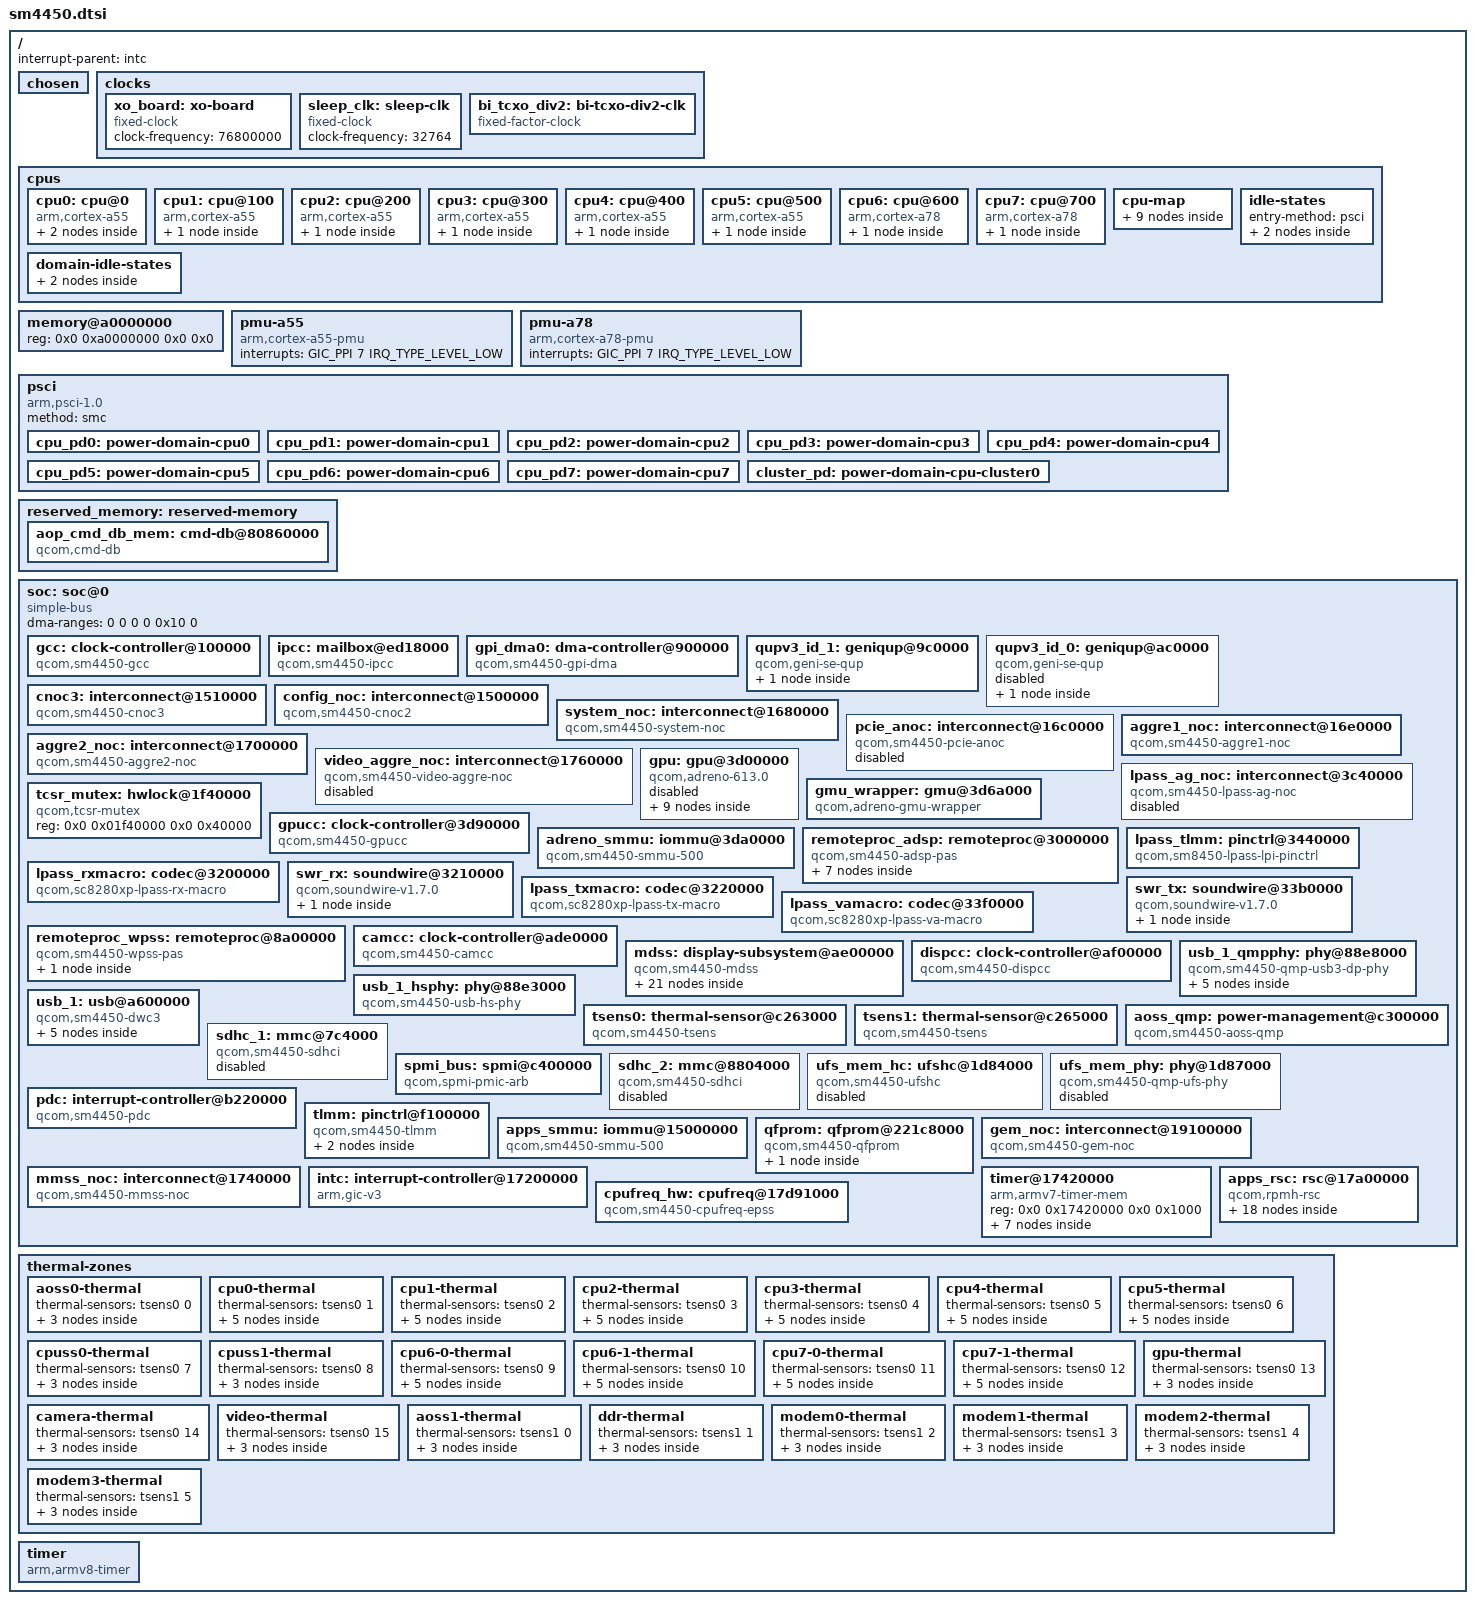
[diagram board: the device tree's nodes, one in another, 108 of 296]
// SPDX-License-Identifier: BSD-3-Clause
/*
 * Copyright (c) 2023, Qualcomm Innovation Center, Inc. All rights reserved.
 */

#include <dt-bindings/clock/qcom,dsi-phy-28nm.h>
#include <dt-bindings/clock/qcom,rpmh.h>
#include <dt-bindings/clock/qcom,sm4450-camcc.h>
#include <dt-bindings/clock/qcom,sm4450-dispcc.h>
#include <dt-bindings/clock/qcom,sm4450-gcc.h>
#include <dt-bindings/clock/qcom,sm4450-gpucc.h>
#include <dt-bindings/dma/qcom-gpi.h>
#include <dt-bindings/gpio/gpio.h>
#include <dt-bindings/interrupt-controller/arm-gic.h>
#include <dt-bindings/interconnect/qcom,icc.h>
#include <dt-bindings/interconnect/qcom,sm4450-rpmh.h>
#include <dt-bindings/mailbox/qcom-ipcc.h>
#include <dt-bindings/power/qcom,rpmhpd.h>
#include <dt-bindings/power/qcom-rpmpd.h>
#include <dt-bindings/soc/qcom,rpmh-rsc.h>
#include <dt-bindings/soc/qcom,gpr.h>
#include <dt-bindings/sound/qcom,q6dsp-lpass-ports.h>
#include <dt-bindings/phy/phy-qcom-qmp.h>
#include <dt-bindings/thermal/thermal.h>

/ {
	interrupt-parent = <&intc>;

	#address-cells = <2>;
	#size-cells = <2>;

	chosen { };

	clocks {
		xo_board: xo-board {
			compatible = "fixed-clock";
			clock-frequency = <76800000>;
			#clock-cells = <0>;
		};

		sleep_clk: sleep-clk {
			compatible = "fixed-clock";
			clock-frequency = <32764>;
			#clock-cells = <0>;
		};

		bi_tcxo_div2: bi-tcxo-div2-clk {
			#clock-cells = <0>;
			compatible = "fixed-factor-clock";
			clocks = <&rpmhcc RPMH_CXO_CLK>;
			clock-mult = <1>;
			clock-div = <2>;
		};
	};

	cpus {
		#address-cells = <2>;
		#size-cells = <0>;

		cpu0: cpu@0 {
			device_type = "cpu";
			compatible = "arm,cortex-a55";
			reg = <0x0 0x0>;
			capacity-dmips-mhz = <1024>;
			dynamic-power-coefficient = <100>;
			clocks = <&cpufreq_hw 0>;
			enable-method = "psci";
			next-level-cache = <&l2_0>;
			power-domains = <&cpu_pd0>;
			power-domain-names = "psci";
			qcom,freq-domain = <&cpufreq_hw 0>;
			#cooling-cells = <2>;

			l2_0: l2-cache {
				compatible = "cache";
				cache-level = <2>;
				cache-unified;
				next-level-cache = <&l3_0>;

				l3_0: l3-cache {
					compatible = "cache";
					cache-level = <3>;
					cache-unified;
				};
			};
		};

		cpu1: cpu@100 {
			device_type = "cpu";
			compatible = "arm,cortex-a55";
			reg = <0x0 0x100>;
			capacity-dmips-mhz = <1024>;
			dynamic-power-coefficient = <100>;
			clocks = <&cpufreq_hw 0>;
			enable-method = "psci";
			next-level-cache = <&l2_100>;
			power-domains = <&cpu_pd0>;
			power-domain-names = "psci";
			qcom,freq-domain = <&cpufreq_hw 0>;
			#cooling-cells = <2>;

			l2_100: l2-cache {
				compatible = "cache";
				cache-level = <2>;
				cache-unified;
				next-level-cache = <&l3_0>;
			};
		};

		cpu2: cpu@200 {
			device_type = "cpu";
			compatible = "arm,cortex-a55";
			reg = <0x0 0x200>;
			capacity-dmips-mhz = <1024>;
			dynamic-power-coefficient = <100>;
			clocks = <&cpufreq_hw 0>;
			enable-method = "psci";
			next-level-cache = <&l2_200>;
			power-domains = <&cpu_pd0>;
			power-domain-names = "psci";
			qcom,freq-domain = <&cpufreq_hw 0>;
			#cooling-cells = <2>;

			l2_200: l2-cache {
				compatible = "cache";
				cache-level = <2>;
				cache-unified;
				next-level-cache = <&l3_0>;
			};
		};

		cpu3: cpu@300 {
			device_type = "cpu";
			compatible = "arm,cortex-a55";
			reg = <0x0 0x300>;
			capacity-dmips-mhz = <1024>;
			dynamic-power-coefficient = <100>;
			clocks = <&cpufreq_hw 0>;
			enable-method = "psci";
			next-level-cache = <&l2_300>;
			power-domains = <&cpu_pd0>;
			power-domain-names = "psci";
			qcom,freq-domain = <&cpufreq_hw 0>;
			#cooling-cells = <2>;

			l2_300: l2-cache {
				compatible = "cache";
				cache-level = <2>;
				cache-unified;
				next-level-cache = <&l3_0>;
			};
		};

		cpu4: cpu@400 {
			device_type = "cpu";
			compatible = "arm,cortex-a55";
			reg = <0x0 0x400>;
			capacity-dmips-mhz = <1024>;
			dynamic-power-coefficient = <100>;
			clocks = <&cpufreq_hw 0>;
			enable-method = "psci";
			next-level-cache = <&l2_400>;
			power-domains = <&cpu_pd0>;
			power-domain-names = "psci";
			qcom,freq-domain = <&cpufreq_hw 0>;
			#cooling-cells = <2>;

			l2_400: l2-cache {
				compatible = "cache";
				cache-level = <2>;
				cache-unified;
				next-level-cache = <&l3_0>;
			};
		};

		cpu5: cpu@500 {
			device_type = "cpu";
			compatible = "arm,cortex-a55";
			reg = <0x0 0x500>;
			capacity-dmips-mhz = <1024>;
			dynamic-power-coefficient = <100>;
			clocks = <&cpufreq_hw 0>;
			enable-method = "psci";
			next-level-cache = <&l2_500>;
			power-domains = <&cpu_pd0>;
			power-domain-names = "psci";
			qcom,freq-domain = <&cpufreq_hw 0>;
			#cooling-cells = <2>;

			l2_500: l2-cache {
				compatible = "cache";
				cache-level = <2>;
				cache-unified;
				next-level-cache = <&l3_0>;
			};
		};

		cpu6: cpu@600 {
			device_type = "cpu";
			compatible = "arm,cortex-a78";
			reg = <0x0 0x600>;
			capacity-dmips-mhz = <1894>;
			dynamic-power-coefficient = <703>;
			clocks = <&cpufreq_hw 1>;
			enable-method = "psci";
			next-level-cache = <&l2_600>;
			power-domains = <&cpu_pd0>;
			power-domain-names = "psci";
			qcom,freq-domain = <&cpufreq_hw 1>;
			#cooling-cells = <2>;

			l2_600: l2-cache {
				compatible = "cache";
				cache-level = <2>;
				cache-unified;
				next-level-cache = <&l3_0>;
			};
		};

		cpu7: cpu@700 {
			device_type = "cpu";
			compatible = "arm,cortex-a78";
			reg = <0x0 0x700>;
			capacity-dmips-mhz = <1894>;
			dynamic-power-coefficient = <703>;
			clocks = <&cpufreq_hw 1>;
			enable-method = "psci";
			next-level-cache = <&l2_700>;
			power-domains = <&cpu_pd0>;
			power-domain-names = "psci";
			qcom,freq-domain = <&cpufreq_hw 1>;
			#cooling-cells = <2>;

			l2_700: l2-cache {
				compatible = "cache";
				cache-level = <2>;
				cache-unified;
				next-level-cache = <&l3_0>;
			};
		};

		cpu-map {
			cluster0 {
				core0 {
					cpu = <&cpu0>;
				};

				core1 {
					cpu = <&cpu1>;
				};

				core2 {
					cpu = <&cpu2>;
				};

				core3 {
					cpu = <&cpu3>;
				};

				core4 {
					cpu = <&cpu4>;
				};

				core5 {
					cpu = <&cpu5>;
				};

				core6 {
					cpu = <&cpu6>;
				};

				core7 {
					cpu = <&cpu7>;
				};
			};
		};

		idle-states {
			entry-method = "psci";

			little_cpu_sleep_0: cpu-sleep-0-0 {
				compatible = "arm,idle-state";
				arm,psci-suspend-param = <0x40000004>;
				entry-latency-us = <800>;
				exit-latency-us = <750>;
				min-residency-us = <4090>;
				local-timer-stop;
			};

			big_cpu_sleep_0: cpu-sleep-1-0 {
				compatible = "arm,idle-state";
				arm,psci-suspend-param = <0x40000004>;
				entry-latency-us = <600>;
				exit-latency-us = <1550>;
				min-residency-us = <4791>;
				local-timer-stop;
			};
		};

		domain-idle-states {
			cluster_sleep_0: cluster-sleep-0 {
				compatible = "domain-idle-state";
				arm,psci-suspend-param = <0x41000044>;
				entry-latency-us = <1050>;
				exit-latency-us = <2500>;
				min-residency-us = <5309>;
			};

			cluster_sleep_1: cluster-sleep-1 {
				compatible = "domain-idle-state";
				arm,psci-suspend-param = <0x41003344>;
				entry-latency-us = <1561>;
				exit-latency-us = <2801>;
				min-residency-us = <8550>;
			};
		};
	};

	memory@a0000000 {
		device_type = "memory";
		/* We expect the bootloader to fill in the size */
		reg = <0x0 0xa0000000 0x0 0x0>;
	};

	pmu-a55 {
		compatible = "arm,cortex-a55-pmu";
		interrupts = <GIC_PPI 7 IRQ_TYPE_LEVEL_LOW>;
	};

	pmu-a78 {
		compatible = "arm,cortex-a78-pmu";
		interrupts = <GIC_PPI 7 IRQ_TYPE_LEVEL_LOW>;
	};

	psci {
		compatible = "arm,psci-1.0";
		method = "smc";

		cpu_pd0: power-domain-cpu0 {
			#power-domain-cells = <0>;
			power-domains = <&cluster_pd>;
			domain-idle-states = <&little_cpu_sleep_0>;
		};

		cpu_pd1: power-domain-cpu1 {
			#power-domain-cells = <0>;
			power-domains = <&cluster_pd>;
			domain-idle-states = <&little_cpu_sleep_0>;
		};

		cpu_pd2: power-domain-cpu2 {
			#power-domain-cells = <0>;
			power-domains = <&cluster_pd>;
			domain-idle-states = <&little_cpu_sleep_0>;
		};

		cpu_pd3: power-domain-cpu3 {
			#power-domain-cells = <0>;
			power-domains = <&cluster_pd>;
			domain-idle-states = <&little_cpu_sleep_0>;
		};

		cpu_pd4: power-domain-cpu4 {
			#power-domain-cells = <0>;
			power-domains = <&cluster_pd>;
			domain-idle-states = <&big_cpu_sleep_0>;
		};

		cpu_pd5: power-domain-cpu5 {
			#power-domain-cells = <0>;
			power-domains = <&cluster_pd>;
			domain-idle-states = <&big_cpu_sleep_0>;
		};

		cpu_pd6: power-domain-cpu6 {
			#power-domain-cells = <0>;
			power-domains = <&cluster_pd>;
			domain-idle-states = <&big_cpu_sleep_0>;
		};

		cpu_pd7: power-domain-cpu7 {
			#power-domain-cells = <0>;
			power-domains = <&cluster_pd>;
			domain-idle-states = <&big_cpu_sleep_0>;
		};

		cluster_pd: power-domain-cpu-cluster0 {
			#power-domain-cells = <0>;
			domain-idle-states = <&cluster_sleep_0>, <&cluster_sleep_1>;
		};
	};

	reserved_memory: reserved-memory {
		#address-cells = <2>;
		#size-cells = <2>;
		ranges;

		aop_cmd_db_mem: cmd-db@80860000 {
			compatible = "qcom,cmd-db";
			reg = <0x0 0x80860000 0x0 0x20000>;
			no-map;
		};
	};

	soc: soc@0 {
		#address-cells = <2>;
		#size-cells = <2>;
		ranges = <0 0 0 0 0x10 0>;
		dma-ranges = <0 0 0 0 0x10 0>;
		compatible = "simple-bus";

		gcc: clock-controller@100000 {
			compatible = "qcom,sm4450-gcc";
			reg = <0x0 0x00100000 0x0 0x1f4200>;
			#clock-cells = <1>;
			#reset-cells = <1>;
			#power-domain-cells = <1>;
			clocks = <&rpmhcc RPMH_CXO_CLK>,
				 <&sleep_clk>,
				 <0>,
				 <0>,
				 <0>,
				 <0>;
		};

		ipcc: mailbox@ed18000 {
			compatible = "qcom,sm4450-ipcc", "qcom,ipcc";
			reg = <0x0 0x0ed18000 0x0 0x1000>;
			interrupts = <GIC_SPI 229 IRQ_TYPE_LEVEL_HIGH>;
			interrupt-controller;
			#interrupt-cells = <3>;
			#mbox-cells = <2>;
		};

		gpi_dma0: dma-controller@900000 {
			compatible = "qcom,sm4450-gpi-dma", "qcom,sm6350-gpi-dma";
			reg = <0x0 0x00900000 0x0 0x60000>;
			interrupts = <GIC_SPI 244 IRQ_TYPE_LEVEL_HIGH>,
				<GIC_SPI 245 IRQ_TYPE_LEVEL_HIGH>,
				<GIC_SPI 246 IRQ_TYPE_LEVEL_HIGH>,
				<GIC_SPI 247 IRQ_TYPE_LEVEL_HIGH>,
				<GIC_SPI 248 IRQ_TYPE_LEVEL_HIGH>,
				<GIC_SPI 249 IRQ_TYPE_LEVEL_HIGH>,
				<GIC_SPI 250 IRQ_TYPE_LEVEL_HIGH>,
				<GIC_SPI 251 IRQ_TYPE_LEVEL_HIGH>,
				<GIC_SPI 252 IRQ_TYPE_LEVEL_HIGH>,
				<GIC_SPI 253 IRQ_TYPE_LEVEL_HIGH>,
				<GIC_SPI 254 IRQ_TYPE_LEVEL_HIGH>,
				<GIC_SPI 255 IRQ_TYPE_LEVEL_HIGH>;
			dma-channels = <12>;
			dma-channel-mask = <0x3e>;
			iommus = <&apps_smmu 0x176 0x0>;
			#dma-cells = <3>;
		};

		qupv3_id_1: geniqup@9c0000 {
			compatible = "qcom,geni-se-qup";
			reg = <0x0 0x009c0000 0x0 0x2000>;
			ranges;
			iommus = <&apps_smmu 0x163 0x0>;
			clocks = <&gcc GCC_QUPV3_WRAP_0_M_AHB_CLK>,
				 <&gcc GCC_QUPV3_WRAP_0_S_AHB_CLK>;
			clock-names = "m-ahb", "s-ahb";
			#address-cells = <2>;
			#size-cells = <2>;
			status = "okay";

			uart2: serial@988000 {
				compatible = "qcom,geni-uart";
				reg = <0x0 0x00988000 0x0 0x4000>;
				clocks = <&gcc GCC_QUPV3_WRAP0_S2_CLK>;
				clock-names = "se";
				interrupts-extended = <&intc GIC_SPI 603 IRQ_TYPE_LEVEL_HIGH>,
					    	  <&tlmm 17 IRQ_TYPE_EDGE_FALLING>;
				interconnects = <&clk_virt MASTER_QUP_CORE_0 QCOM_ICC_TAG_ALWAYS
						 &clk_virt SLAVE_QUP_CORE_0 QCOM_ICC_TAG_ALWAYS>,
						<&gem_noc MASTER_APPSS_PROC QCOM_ICC_TAG_ALWAYS
					 	&config_noc SLAVE_QUP_0 QCOM_ICC_TAG_ALWAYS>;
				interconnect-names = "qup-core", "qup-config";
				pinctrl-0 = <&qup_uart2_default>;
				pinctrl-1 = <&qup_uart2_sleep>;
				pinctrl-names = "default", "sleep";
				status = "okay";
			};
		};
		
		qupv3_id_0: geniqup@ac0000 {
			compatible = "qcom,geni-se-qup";
			reg = <0x0 0x00ac0000 0x0 0x2000>;
			ranges;
			clocks = <&gcc GCC_QUPV3_WRAP_1_M_AHB_CLK>,
				 <&gcc GCC_QUPV3_WRAP_1_S_AHB_CLK>;
			clock-names = "m-ahb", "s-ahb";
			#address-cells = <2>;
			#size-cells = <2>;
			status = "disabled";

			uart7: serial@a88000 {
				compatible = "qcom,geni-debug-uart";
				reg = <0x0 0x00a88000 0x0 0x4000>;
				clocks = <&gcc GCC_QUPV3_WRAP1_S2_CLK>;
				clock-names = "se";
				interrupts = <GIC_SPI 355 IRQ_TYPE_LEVEL_HIGH>;
				pinctrl-0 = <&qup_uart7_tx>, <&qup_uart7_rx>;
				pinctrl-names = "default";
				status = "disabled";
			};
		};

		cnoc3: interconnect@1510000 {
			compatible = "qcom,sm4450-cnoc3";
			reg = <0x0 0x01510000 0x0 0xf200>;
			#interconnect-cells = <2>;
			qcom,bcm-voters = <&apps_bcm_voter>;
		};

		config_noc: interconnect@1500000 {
			compatible = "qcom,sm4450-cnoc2";
			reg = <0x0 0x01500000 0x0 0x6200>;
			#interconnect-cells = <2>;
			qcom,bcm-voters = <&apps_bcm_voter>;
		};

		system_noc: interconnect@1680000 {
			compatible = "qcom,sm4450-system-noc";
			reg = <0x0 0x01680000 0x0 0x19080>;
			#interconnect-cells = <2>;
			qcom,bcm-voters = <&apps_bcm_voter>;
		};

		pcie_anoc: interconnect@16c0000 {
			compatible = "qcom,sm4450-pcie-anoc";
			reg = <0x0 0x016c0000 0x0 0x7080>;
			#interconnect-cells = <2>;
			qcom,bcm-voters = <&apps_bcm_voter>;
			status = "disabled";
		};

		aggre1_noc: interconnect@16e0000 {
			compatible = "qcom,sm4450-aggre1-noc";
			reg = <0x0 0x016e0000 0x0 0x13080>;
			#interconnect-cells = <2>;
			clocks = <&gcc GCC_SDCC2_AHB_CLK>;
			qcom,bcm-voters = <&apps_bcm_voter>;
		};

		aggre2_noc: interconnect@1700000 {
			compatible = "qcom,sm4450-aggre2-noc";
			reg = <0x0 0x01700000 0x0 0x1b080>;
			#interconnect-cells = <2>;
			clocks = <&rpmhcc RPMH_IPA_CLK>,
				 <&gcc GCC_AGGRE_USB3_PRIM_AXI_CLK>;
			qcom,bcm-voters = <&apps_bcm_voter>;
		};

		video_aggre_noc: interconnect@1760000 {
			compatible = "qcom,sm4450-video-aggre-noc";
			reg = <0x0 0x01760000 0x0 0x1100>;
			#interconnect-cells = <2>;
			qcom,bcm-voters = <&apps_bcm_voter>;
			status = "disabled";
		};

		lpass_ag_noc: interconnect@3c40000 {
			compatible = "qcom,sm4450-lpass-ag-noc";
			reg = <0x0 0x03c40000 0x0 0x17200>;
			#interconnect-cells = <2>;
			qcom,bcm-voters = <&apps_bcm_voter>;
			status = "disabled";
		};

		gpu: gpu@3d00000 {
			status = "disabled";
			compatible = "qcom,adreno-613.0", "qcom,adreno";
			reg = <0x0 0x03d00000 0x0 0x40000>,
				<0x0 0x03d9e000 0x0 0x1000>,
				<0x0 0x03d61000 0x0 0x800>;
			reg-names = "kgsl_3d0_reg_memory",
				"cx_mem",
				"cx_dbgc";

			interrupts = <GIC_SPI 300 IRQ_TYPE_LEVEL_HIGH>;

			clocks = <&gpucc GPU_CC_GX_GFX3D_CLK>,
				<&gpucc GPU_CC_AHB_CLK>,
				<&gcc GCC_DDRSS_GPU_AXI_CLK>,
				<&gcc GCC_GPU_MEMNOC_GFX_CLK>,
				<&gpucc GPU_CC_CX_GMU_CLK>,
				<&gpucc GPU_CC_CXO_CLK>,
				<&gpucc GPU_CC_HUB_CX_INT_CLK>;
			clock-names = "core",
					"iface",
					"mem_iface",
					"alt_mem_iface",
					"gmu",
					"xo",
					"hub";

			interconnects = <&gem_noc MASTER_GFX3D QCOM_ICC_TAG_ALWAYS
					&mc_virt SLAVE_EBI1 QCOM_ICC_TAG_ALWAYS>;
			interconnect-names = "gfx-mem";

			iommus = <&adreno_smmu 0 0x400>;
			power-domains = <&rpmhpd RPMHPD_CX>;

			operating-points-v2 = <&gpu_opp_table>;

			qcom,gmu = <&gmu_wrapper>;

			nvmem-cells = <&gpu_speed_bin>;
			nvmem-cell-names = "speed_bin";

			#cooling-cells = <2>;


			zap-shader {
				memory-region = <&gpu_microcode_mem>;
				firmware-name = "qcom/sm4450/a613_zap.mbn";
			};

			gpu_opp_table: opp-table {
				compatible = "operating-points-v2";

				opp-340000000 {
					opp-hz = /bits/ 64 <340000000>;
					required-opps = <&rpmhpd_opp_low_svs>;
					opp-peak-kBps = <2136718>;
					opp-supported-hw = <0xf>;
				};

				opp-500000000 {
					opp-hz = /bits/ 64 <500000000>;
					required-opps = <&rpmhpd_opp_svs>;
					opp-peak-kBps = <3972656>;
					opp-supported-hw = <0xf>;
				};

				opp-605000000 {
					opp-hz = /bits/ 64 <605000000>;
					required-opps = <&rpmhpd_opp_svs_l1>;
					opp-peak-kBps = <5285156>;
					opp-supported-hw = <0xf>;
				};

				opp-765000000 {
					opp-hz = /bits/ 64 <765000000>;
					required-opps = <&rpmhpd_opp_nom>;
					opp-peak-kBps = <6671875>;
					opp-supported-hw = <0xf>;
				};

				opp-850000000 {
					opp-hz = /bits/ 64 <850000000>;
					required-opps = <&rpmhpd_opp_nom_l1>;
					opp-peak-kBps = <8332031>;
					opp-supported-hw = <0x7>;
				};

				opp-955000000 {
					opp-hz = /bits/ 64 <955000000>;
					required-opps = <&rpmhpd_opp_turbo>;
					opp-peak-kBps = <8332031>;
					opp-supported-hw = <0x7>;
				};

				opp-1010000000 {
					opp-hz = /bits/ 64 <1010000000>;
					required-opps = <&rpmhpd_opp_turbo_l1>;
					opp-peak-kBps = <8332031>;
					opp-supported-hw = <0x5>;
				};
			};
		};

		gmu_wrapper: gmu@3d6a000 {
			compatible = "qcom,adreno-gmu-wrapper";
			reg = <0x0 0x03d6a000 0x0 0x30000>;
			reg-names = "gmu";
			power-domains = <&gpucc GPU_CC_CX_GDSC>,
					<&gpucc GPU_CC_GX_GDSC>;
			power-domain-names = "cx", "gx";
			status = "okay";
		};

		tcsr_mutex: hwlock@1f40000 {
			compatible = "qcom,tcsr-mutex";
			reg = <0x0 0x01f40000 0x0 0x40000>;
			#hwlock-cells = <1>;
		};

		gpucc: clock-controller@3d90000 {
			compatible = "qcom,sm4450-gpucc";
			reg = <0x0 0x03d90000 0x0 0xa000>;
			clocks = <&rpmhcc RPMH_CXO_CLK>,
				 <&gcc GCC_GPU_GPLL0_CLK_SRC>,
				 <&gcc GCC_GPU_GPLL0_DIV_CLK_SRC>;
			#clock-cells = <1>;
			#reset-cells = <1>;
			#power-domain-cells = <1>;
		};

		adreno_smmu: iommu@3da0000 {
			compatible = "qcom,sm4450-smmu-500", "qcom,adreno-smmu",
				     "qcom,smmu-500", "arm,mmu-500";
			reg = <0x0 0x03da0000 0x0 0x10000>;
			#iommu-cells = <2>;
			#global-interrupts = <1>;
			dma-coherent;
			interrupts = <GIC_SPI 674 IRQ_TYPE_LEVEL_HIGH>,
				<GIC_SPI 678 IRQ_TYPE_LEVEL_HIGH>,
				<GIC_SPI 679 IRQ_TYPE_LEVEL_HIGH>,
				<GIC_SPI 680 IRQ_TYPE_LEVEL_HIGH>,
				<GIC_SPI 681 IRQ_TYPE_LEVEL_HIGH>,
				<GIC_SPI 682 IRQ_TYPE_LEVEL_HIGH>,
				<GIC_SPI 683 IRQ_TYPE_LEVEL_HIGH>,
				<GIC_SPI 684 IRQ_TYPE_LEVEL_HIGH>,
				<GIC_SPI 685 IRQ_TYPE_LEVEL_HIGH>,
				<GIC_SPI 686 IRQ_TYPE_LEVEL_HIGH>,
				<GIC_SPI 687 IRQ_TYPE_LEVEL_HIGH>,
				<GIC_SPI 688 IRQ_TYPE_LEVEL_HIGH>,
				<GIC_SPI 422 IRQ_TYPE_LEVEL_HIGH>;

			clocks = <&gpucc GPU_CC_CX_GMU_CLK>,
				 <&gpucc GPU_CC_HUB_CX_INT_CLK>,
				 <&gpucc GPU_CC_HLOS1_VOTE_GPU_SMMU_CLK>,
				 <&gcc GCC_GPU_MEMNOC_GFX_CLK>,
				 <&gcc GCC_GPU_SNOC_DVM_GFX_CLK>,
				 <&gpucc GPU_CC_AHB_CLK>;
			clock-names = "gmu",
			      	"hub",
			      	"hlos",
			      	"bus",
			      	"iface",
				      "ahb";

			power-domains = <&gpucc GPU_CC_CX_GDSC>;
			status = "okay";
		};

		remoteproc_adsp: remoteproc@3000000 {
			compatible = "qcom,sm4450-adsp-pas";
			reg = <0x0 0x03000000 0x0 0x10000>;

			interrupts-extended = <&pdc 6 IRQ_TYPE_EDGE_RISING>,
						<&smp2p_adsp_in 0 IRQ_TYPE_EDGE_RISING>,
						<&smp2p_adsp_in 1 IRQ_TYPE_EDGE_RISING>,
						<&smp2p_adsp_in 2 IRQ_TYPE_EDGE_RISING>,
						<&smp2p_adsp_in 3 IRQ_TYPE_EDGE_RISING>;
			interrupt-names = "wdog", "fatal", "ready",
					  "handover", "stop-ack";

			clocks = <&rpmhcc RPMH_CXO_CLK>;
			clock-names = "xo";

			power-domains = <&rpmhpd RPMHPD_LCX>,
					<&rpmhpd RPMHPD_LMX>;
			power-domain-names = "lcx", "lmx";

			memory-region = <&adsp_mem>;

			qcom,qmp = <&aoss_qmp>;
			qcom,smem-states = <&smp2p_adsp_out 0>;
			qcom,smem-state-names = "stop";

			firmware-name = "qcom/sm4450/RG55G1/adsp.mbn";

			glink-edge {
				interrupts-extended = <&ipcc IPCC_CLIENT_LPASS
							     IPCC_MPROC_SIGNAL_GLINK_QMP
							     IRQ_TYPE_EDGE_RISING>;
				mboxes = <&ipcc IPCC_CLIENT_LPASS
						IPCC_MPROC_SIGNAL_GLINK_QMP>;
				label = "lpass";
				qcom,remote-pid = <2>;

				gpr {
					compatible = "qcom,gpr";
					qcom,glink-channels = "adsp_apps";
					qcom,domain = <GPR_DOMAIN_ID_ADSP>;
					qcom,intents = <512 20>;
					#address-cells = <1>;
					#size-cells = <0>;

					q6apm: service@1 {
						compatible = "qcom,q6apm";
						reg = <GPR_APM_MODULE_IID>;
						#sound-dai-cells = <0>;
						qcom,protection-domain = "avs/audio",
									 "msm/adsp/audio_pd";

						q6apmdai: dais {
							compatible = "qcom,q6apm-dais";
							iommus = <&apps_smmu 0x1001 0x0>;
						};

						q6apmbedai: bedais {
							compatible = "qcom,q6apm-lpass-dais";
							#sound-dai-cells = <1>;
						};
					};

					q6prm: service@2 {
						compatible = "qcom,q6prm";
						reg = <GPR_PRM_MODULE_IID>;
						qcom,protection-domain = "avs/audio",
									 "msm/adsp/audio_pd";

						q6prmcc: clock-controller {
							compatible = "qcom,q6prm-lpass-clocks";
							#clock-cells = <2>;
						};
					};
				};
			};
		};

		lpass_tlmm: pinctrl@3440000 {
			compatible = "qcom,sm8450-lpass-lpi-pinctrl";
			reg = <0x0 0x03440000 0x0 0x20000>,
		    	  <0x0 0x034d0000 0x0 0x10000>;

			clocks = <&q6prmcc LPASS_HW_DCODEC_VOTE LPASS_CLK_ATTRIBUTE_COUPLE_NO>;
			clock-names = "audio";
			gpio-controller;
			#gpio-cells = <2>;
			gpio-ranges = <&lpass_tlmm 0 0 23>;
		};

		lpass_rxmacro: codec@3200000 {
			compatible = "qcom,sc8280xp-lpass-rx-macro";
			reg = <0x0 0x03200000 0x0 0x1000>;
			clocks = <&q6prmcc LPASS_CLK_ID_RX_CORE_TX_MCLK LPASS_CLK_ATTRIBUTE_COUPLE_NO>,
				 <&q6prmcc LPASS_CLK_ID_RX_CORE_TX_2X_MCLK LPASS_CLK_ATTRIBUTE_COUPLE_NO>,
				 <&q6prmcc LPASS_HW_DCODEC_VOTE LPASS_CLK_ATTRIBUTE_COUPLE_NO>,
				 <&q6prmcc LPASS_HW_DCODEC_VOTE LPASS_CLK_ATTRIBUTE_COUPLE_NO>,
				 <&lpass_vamacro>;
			clock-names = "mclk", "npl", "macro", "dcodec", "fsgen";
			assigned-clocks = <&q6prmcc LPASS_CLK_ID_RX_CORE_TX_MCLK LPASS_CLK_ATTRIBUTE_COUPLE_NO>,
					  <&q6prmcc LPASS_CLK_ID_RX_CORE_TX_2X_MCLK LPASS_CLK_ATTRIBUTE_COUPLE_NO>;
			assigned-clock-rates = <19200000>, <19200000>;

			#clock-cells = <0>;
			clock-output-names = "mclk";
			#sound-dai-cells = <1>;
		};

		swr_rx: soundwire@3210000 {
			compatible = "qcom,soundwire-v1.7.0";
			reg = <0x0 0x03210000 0x0 0x2000>;
			interrupts = <GIC_SPI 155 IRQ_TYPE_LEVEL_HIGH>;
			clocks = <&lpass_rxmacro>;
			clock-names = "iface";
			label = "RX";

			pinctrl-0 = <&rx_swr_active>;
			pinctrl-names = "default";

			qcom,din-ports = <0>;
			qcom,dout-ports = <5>;

			qcom,ports-word-length =	/bits/ 8 <0x01 0x07 0x04 0xff 0xff>;
			qcom,ports-sinterval-low =	/bits/ 8 <0x03 0x3f 0x1f 0x03 0x03>;
			qcom,ports-offset1 =		/bits/ 8 <0x00 0x00 0x0b 0x01 0x01>;
			qcom,ports-offset2 =		/bits/ 8 <0x00 0x00 0x0b 0x00 0x00>;
			qcom,ports-lane-control =	/bits/ 8 <0x01 0x00 0x00 0x00 0x00>;
			qcom,ports-block-pack-mode =	/bits/ 8 <0xff 0x00 0x01 0xff 0xff>;
			qcom,ports-hstart =		/bits/ 8 <0xff 0x03 0xff 0xff 0xff>;
			qcom,ports-hstop =		/bits/ 8 <0xff 0x06 0xff 0xff 0xff>;
			qcom,ports-block-group-count =	/bits/ 8 <0xff 0xff 0xff 0xff 0x00>;

			#sound-dai-cells = <1>;
			#address-cells = <2>;
			#size-cells = <0>;

			wcd937x_rx: codec@0,4 {
				compatible = "sdw20217010a00";
				reg = <0 4>;
				qcom,rx-port-mapping = <1 2 3 4 5>;
			};
		};

		lpass_txmacro: codec@3220000 {
			compatible = "qcom,sc8280xp-lpass-tx-macro";
			reg = <0x0 0x03220000 0x0 0x1000>;
			clocks = <&q6prmcc LPASS_CLK_ID_TX_CORE_MCLK LPASS_CLK_ATTRIBUTE_COUPLE_NO>,
				 <&q6prmcc LPASS_CLK_ID_TX_CORE_NPL_MCLK LPASS_CLK_ATTRIBUTE_COUPLE_NO>,
				 <&q6prmcc LPASS_HW_DCODEC_VOTE LPASS_CLK_ATTRIBUTE_COUPLE_NO>,
				 <&q6prmcc LPASS_HW_DCODEC_VOTE LPASS_CLK_ATTRIBUTE_COUPLE_NO>,
			 <&lpass_vamacro>;
			clock-names = "mclk", "npl", "macro", "dcodec", "fsgen";
			assigned-clocks = <&q6prmcc LPASS_CLK_ID_TX_CORE_MCLK LPASS_CLK_ATTRIBUTE_COUPLE_NO>,
					  <&q6prmcc LPASS_CLK_ID_TX_CORE_NPL_MCLK LPASS_CLK_ATTRIBUTE_COUPLE_NO>;
			assigned-clock-rates = <19200000>, <19200000>;

			#clock-cells = <0>;
			clock-output-names = "mclk";
			#sound-dai-cells = <1>;
		};

		swr_tx: soundwire@33b0000 {
			compatible = "qcom,soundwire-v1.7.0";
			reg = <0x0 0x033b0000 0x0 0x2000>;
			interrupts = <GIC_SPI 496 IRQ_TYPE_LEVEL_HIGH>,
				     <GIC_SPI 520 IRQ_TYPE_LEVEL_HIGH>;
			interrupt-names = "core", "wakeup";
			clocks = <&lpass_txmacro>;
			clock-names = "iface";
			label = "TX";

			pinctrl-0 = <&tx_swr_active>;
			pinctrl-names = "default";

			qcom,din-ports = <3>;
			qcom,dout-ports = <0>;

			qcom,ports-sinterval-low =	/bits/ 8 <0x01 0x03 0x03>;
			qcom,ports-offset1 =		/bits/ 8 <0x01 0x00 0x02>;
			qcom,ports-offset2 =		/bits/ 8 <0x00 0x00 0x00>;
			qcom,ports-hstart =		/bits/ 8 <0xff 0xff 0xff>;
			qcom,ports-hstop =		/bits/ 8 <0xff 0xff 0xff>;
			qcom,ports-word-length =	/bits/ 8 <0xff 0x00 0xff>;
			qcom,ports-block-pack-mode =	/bits/ 8 <0xff 0xff 0xff>;
			qcom,ports-block-group-count =	/bits/ 8 <0xff 0xff 0xff>;
			qcom,ports-lane-control =	/bits/ 8 <0x00 0x01 0x00>;

			#sound-dai-cells = <1>;
			#address-cells = <2>;
			#size-cells = <0>;

			wcd937x_tx: codec@0,3 {
				compatible = "sdw20217010a00";
				reg = <0 3>;
				qcom,tx-port-mapping = <1 1 2 3>;
			};
		};

		lpass_vamacro: codec@33f0000 {
			compatible = "qcom,sc8280xp-lpass-va-macro";
			reg = <0x0 0x033f0000 0x0 0x1000>;
			clocks = <&q6prmcc LPASS_CLK_ID_TX_CORE_MCLK LPASS_CLK_ATTRIBUTE_COUPLE_NO>,
				 <&q6prmcc LPASS_HW_DCODEC_VOTE LPASS_CLK_ATTRIBUTE_COUPLE_NO>,
				 <&q6prmcc LPASS_HW_DCODEC_VOTE LPASS_CLK_ATTRIBUTE_COUPLE_NO>,
				 <&q6prmcc LPASS_CLK_ID_TX_CORE_NPL_MCLK LPASS_CLK_ATTRIBUTE_COUPLE_NO>;
			clock-names = "mclk", "macro", "dcodec", "npl";
			assigned-clocks = <&q6prmcc LPASS_CLK_ID_TX_CORE_MCLK LPASS_CLK_ATTRIBUTE_COUPLE_NO>;
			assigned-clock-rates = <19200000>;
			qcom,dmic-sample-rate = <600000>;

			#clock-cells = <0>;
			clock-output-names = "fsgen";
			#sound-dai-cells = <1>;
		};

		remoteproc_wpss: remoteproc@8a00000 {
			compatible = "qcom,sm4450-wpss-pas";
			reg = <0x0 0x08a00000 0x0 0x10000>;

			interrupts-extended = <&intc GIC_SPI 587 IRQ_TYPE_EDGE_RISING>,
					<&smp2p_wpss_in 0 IRQ_TYPE_EDGE_RISING>,
					<&smp2p_wpss_in 1 IRQ_TYPE_EDGE_RISING>,
					<&smp2p_wpss_in 2 IRQ_TYPE_EDGE_RISING>,
					<&smp2p_wpss_in 3 IRQ_TYPE_EDGE_RISING>;
			interrupt-names = "wdog", "fatal", "ready",
					  "handover", "stop-ack";

			clocks = <&rpmhcc RPMH_CXO_CLK>;
			clock-names = "xo";

			power-domains = <&rpmhpd RPMHPD_CX>,
					<&rpmhpd RPMHPD_MX>;
			power-domain-names = "cx", "mx";

			memory-region = <&wpss_mem>;

			qcom,qmp = <&aoss_qmp>;
			qcom,smem-states = <&smp2p_wpss_out 0>;
			qcom,smem-state-names = "stop";

			firmware-name = "qcom/sm4450/RG55G1/wpss.mbn";

			glink-edge {
				interrupts-extended = <&ipcc IPCC_CLIENT_WPSS
							     IPCC_MPROC_SIGNAL_GLINK_QMP
							     IRQ_TYPE_EDGE_RISING>;
				mboxes = <&ipcc IPCC_CLIENT_WPSS
						IPCC_MPROC_SIGNAL_GLINK_QMP>;
				label = "wpss";
				qcom,remote-pid = <13>;
			};
		};

		camcc: clock-controller@ade0000 {
			compatible = "qcom,sm4450-camcc";
			reg = <0x0 0x0ade0000 0x0 0x20000>;
			clocks = <&rpmhcc RPMH_CXO_CLK>,
				 <&gcc GCC_CAMERA_AHB_CLK>;
			#clock-cells = <1>;
			#reset-cells = <1>;
			#power-domain-cells = <1>;
		};

		mdss: display-subsystem@ae00000 {
			compatible = "qcom,sm4450-mdss";
			reg = <0x0 0x0ae00000 0x0 0x1000>;
			reg-names = "mdss";

			interrupts = <GIC_SPI 83 IRQ_TYPE_LEVEL_HIGH>;
			interrupt-controller;
			#interrupt-cells = <1>;

			clocks = <&dispcc DISP_CC_MDSS_AHB_CLK>,
				 <&gcc GCC_DISP_HF_AXI_CLK>,
				 <&dispcc DISP_CC_MDSS_MDP_CLK>;
			clock-names = "iface", "bus", "core";

			power-domains = <&dispcc DISP_CC_MDSS_CORE_GDSC>;

			interconnects = <&mmss_noc MASTER_MDP QCOM_ICC_TAG_ALWAYS
					 &mc_virt SLAVE_EBI1 QCOM_ICC_TAG_ALWAYS>,
					<&gem_noc MASTER_APPSS_PROC QCOM_ICC_TAG_ACTIVE_ONLY
					 &config_noc SLAVE_DISPLAY_CFG QCOM_ICC_TAG_ACTIVE_ONLY>;
			interconnect-names = "mdp0-mem", "cpu-cfg";

			iommus = <&apps_smmu 0x800 0x402>;

			#address-cells = <2>;
			#size-cells = <2>;
			ranges;


			mdss_mdp: display-controller@ae01000 {
				compatible = "qcom,sm4450-dpu";
				reg = <0x0 0x0ae01000 0x0 0x8f000>,
				      <0x0 0x0aeb0000 0x0 0x2008>;
				reg-names = "mdp", "vbif";

				clocks = <&gcc GCC_DISP_HF_AXI_CLK>,
					 <&dispcc DISP_CC_MDSS_AHB_CLK>,
					 <&dispcc DISP_CC_MDSS_MDP_LUT_CLK>,
					 <&dispcc DISP_CC_MDSS_MDP_CLK>,
					 <&dispcc DISP_CC_MDSS_VSYNC_CLK>;
				clock-names = "bus",
					"iface",
					"lut",
					"core",
					"vsync";

				assigned-clocks = <&dispcc DISP_CC_MDSS_VSYNC_CLK>;
				assigned-clock-rates = <19200000>;

				operating-points-v2 = <&mdp_opp_table>;
				power-domains = <&rpmhpd RPMHPD_CX>;

				interrupt-parent = <&mdss>;
				interrupts = <0>;

				ports {
					#address-cells = <1>;
					#size-cells = <0>;

					port@0 {
						reg = <0>;
						dpu_intf1_out: endpoint {
							remote-endpoint = <&mdss_dsi0_in>;
						};
					};
				};

				mdp_opp_table: opp-table {
					compatible = "operating-points-v2";

					opp-200000000 {
						opp-hz = /bits/ 64 <200000000>;
						required-opps = <&rpmhpd_opp_low_svs>;
				};

					opp-325000000 {
						opp-hz = /bits/ 64 <325000000>;
						required-opps = <&rpmhpd_opp_svs>;
					};

					opp-380000000 {
						opp-hz = /bits/ 64 <380000000>;
						required-opps = <&rpmhpd_opp_svs_l1>;
					};

					opp-506000000 {
						opp-hz = /bits/ 64 <506000000>;
						required-opps = <&rpmhpd_opp_nom>;
					};

					opp-608000000 {
						opp-hz = /bits/ 64 <608000000>;
						required-opps = <&rpmhpd_opp_turbo>;
					};
				};
			};

			mdss_dsi0: dsi@ae94000 {
				compatible = "qcom,sm4450-dsi-ctrl", "qcom,mdss-dsi-ctrl";
				reg = <0x0 0x0ae94000 0x0 0x400>;
				reg-names = "dsi_ctrl";

				interrupt-parent = <&mdss>;
				interrupts = <4>;

				clocks = <&dispcc DISP_CC_MDSS_BYTE0_CLK>,
					<&dispcc DISP_CC_MDSS_BYTE0_INTF_CLK>,
					<&dispcc DISP_CC_MDSS_PCLK0_CLK>,
					<&dispcc DISP_CC_MDSS_ESC0_CLK>,
					<&dispcc DISP_CC_MDSS_AHB_CLK>,
					<&gcc GCC_DISP_HF_AXI_CLK>;
				clock-names = "byte",
					"byte_intf",
					"pixel",
					"core",
					"iface",
					"bus";

				assigned-clocks = <&dispcc DISP_CC_MDSS_BYTE0_CLK_SRC>,
						  <&dispcc DISP_CC_MDSS_PCLK0_CLK_SRC>;
				assigned-clock-parents = <&mdss_dsi0_phy DSI_BYTE_PLL_CLK>,
							 <&mdss_dsi0_phy DSI_PIXEL_PLL_CLK>;

				operating-points-v2 = <&mdss_dsi_opp_table>;
				power-domains = <&rpmhpd RPMHPD_CX>;

				phys = <&mdss_dsi0_phy>;
				phy-names = "dsi";

				vdda-supply = <&vreg_l16b_1p2>;

				#address-cells = <1>;
				#size-cells = <0>;

				ports {
					#address-cells = <1>;
					#size-cells = <0>;

					port@0 {
						reg = <0>;
						mdss_dsi0_in: endpoint {
							remote-endpoint = <&dpu_intf1_out>;
						};
					};

					port@1 {
						reg = <1>;
						mdss_dsi0_out: endpoint {
							remote-endpoint = <&panel_in>;
							data-lanes = <0 1 2 3>;
						};
					};
				};

				mdss_dsi_opp_table: opp-table {
					compatible = "operating-points-v2";

					opp-187500000 {
						opp-hz = /bits/ 64 <187500000>;
						required-opps = <&rpmhpd_opp_low_svs>;
					};

					opp-300000000 {
						opp-hz = /bits/ 64 <300000000>;
						required-opps = <&rpmhpd_opp_svs>;
					};

					opp-358000000 {
						opp-hz = /bits/ 64 <358000000>;
						required-opps = <&rpmhpd_opp_svs_l1>;
					};
				};
			};

			mdss_dsi0_phy: phy@ae94400 {
				compatible = "qcom,sm4450-dsi-phy-5nm", "qcom,sm8450-dsi-phy-5nm";
				reg = <0x0 0x0ae94400 0x0 0x200>,
					<0x0 0x0ae94600 0x0 0x280>,
					<0x0 0x0ae94900 0x0 0x260>;
				reg-names = "dsi_phy",
					    "dsi_phy_lane",
					    "dsi_pll";

				#clock-cells = <1>;
				#phy-cells = <0>;

				clocks = <&dispcc DISP_CC_MDSS_AHB_CLK>,
						 <&rpmhcc RPMH_CXO_CLK>;
				clock-names = "iface", "ref";
				vdds-supply = <&vreg_l5b_0p88>;
			};
		};

		dispcc: clock-controller@af00000 {
			compatible = "qcom,sm4450-dispcc";
			reg = <0x0 0x0af00000 0x0 0x20000>;
			clocks = <&rpmhcc RPMH_CXO_CLK>,
				 <&rpmhcc RPMH_CXO_CLK_A>,
				 <&gcc GCC_DISP_AHB_CLK>,
				 <&sleep_clk>,
				 <0>,
				 <0>;
			#clock-cells = <1>;
			#reset-cells = <1>;
			#power-domain-cells = <1>;
		};

		usb_1_qmpphy: phy@88e8000 {
			compatible = "qcom,sm4450-qmp-usb3-dp-phy",
				     "qcom,sm8350-qmp-usb3-dp-phy";
			reg = <0x0 0x088e8000 0x0 0x3000>;

			clocks = <&gcc GCC_USB3_PRIM_PHY_AUX_CLK>,
				 <&rpmhcc RPMH_CXO_CLK>,
				 <&gcc GCC_USB3_PRIM_PHY_COM_AUX_CLK>,
				 <&gcc GCC_USB3_PRIM_PHY_PIPE_CLK>;
			clock-names = "aux", "ref", "com_aux", "usb3_pipe";

			resets = <&gcc GCC_USB3_DP_PHY_PRIM_BCR>,
				 <&gcc GCC_USB3_PHY_PRIM_BCR>;
			reset-names = "phy", "common";

			#clock-cells = <1>;
			#phy-cells = <1>;

			vdda-phy-supply = <&vreg_l7b_0p912>;
			vdda-pll-supply = <&vreg_l16b_1p2>;

			orientation-switch;

			ports {
				#address-cells = <1>;
				#size-cells = <0>;

				port@0 {
					reg = <0>;

					usb_1_qmpphy_out: endpoint {
						remote-endpoint = <&pmic_glink_ss_in>;
					};
				};

				port@1 {
					reg = <1>;

					usb_1_qmpphy_usb_ss_in: endpoint {
						remote-endpoint = <&usb_1_dwc3_ss>;
					};
				};
			};
		};

		usb_1_hsphy: phy@88e3000 {
			compatible = "qcom,sm4450-usb-hs-phy",
				     "qcom,usb-snps-hs-7nm-phy";
			reg = <0x0 0x088e3000 0x0 0x120>;
			#phy-cells = <0>;
			clocks = <&gcc GCC_EUSB3_0_CLKREF_EN>;
			clock-names = "ref";
			resets = <&gcc GCC_QUSB2PHY_PRIM_BCR>;
			vdda-pll-supply = <&vreg_l5b_0p88>;
			vdda18-supply = <&vreg_l23b_1p8>;
			vdda33-supply = <&vreg_l25b_3p072>;

			qcom,hs-disconnect-bp = <1743>;
			qcom,squelch-detector-bp = <(-530)>;
		};

		usb_1: usb@a600000 {
			compatible = "qcom,sm4450-dwc3", "qcom,snps-dwc3";
			reg = <0x0 0x0a600000 0x0 0xfc100>;

			clocks = <&gcc GCC_CFG_NOC_USB3_PRIM_AXI_CLK>,
				 <&gcc GCC_USB30_PRIM_MASTER_CLK>,
				 <&gcc GCC_AGGRE_USB3_PRIM_AXI_CLK>,
				 <&gcc GCC_USB30_PRIM_SLEEP_CLK>,
				 <&gcc GCC_USB30_PRIM_MOCK_UTMI_CLK>,
				 <&gcc GCC_USB3_0_CLKREF_EN>;
			clock-names = "cfg_noc",
			    	  "core",
			    	  "iface",
			    	  "sleep",
			    	  "mock_utmi",
				      "xo";

			assigned-clocks = <&gcc GCC_USB30_PRIM_MOCK_UTMI_CLK>,
					  <&gcc GCC_USB30_PRIM_MASTER_CLK>;
			assigned-clock-rates = <19200000>, <133333333>;

			interrupts-extended = <&intc GIC_SPI 133 IRQ_TYPE_LEVEL_HIGH>,
				    	  <&intc GIC_SPI 130 IRQ_TYPE_LEVEL_HIGH>,
				    	  <&intc GIC_SPI 131 IRQ_TYPE_LEVEL_HIGH>,
				    	  <&pdc 14 IRQ_TYPE_EDGE_BOTH>,
					      <&pdc 15 IRQ_TYPE_EDGE_BOTH>,
					      <&pdc 17 IRQ_TYPE_LEVEL_HIGH>;
			interrupt-names = "dwc_usb3",
					  "pwr_event",
					  "hs_phy_irq",
					  "dp_hs_phy_irq",
					  "dm_hs_phy_irq",
					  "ss_phy_irq";

			power-domains = <&gcc GCC_USB30_PRIM_GDSC>;

			resets = <&gcc GCC_USB30_PRIM_BCR>;

			interconnects = <&aggre2_noc MASTER_USB3_0 QCOM_ICC_TAG_ALWAYS
					 &mc_virt SLAVE_EBI1 QCOM_ICC_TAG_ALWAYS>,
					<&gem_noc MASTER_APPSS_PROC QCOM_ICC_TAG_ALWAYS
					 &config_noc SLAVE_USB3_0 QCOM_ICC_TAG_ALWAYS>;
			interconnect-names = "usb-ddr", "apps-usb";

			snps,dis_u2_susphy_quirk;
			snps,dis_enblslpm_quirk;
			snps,dis_u3_susphy_quirk;

			phys = <&usb_1_hsphy>;
			phy-names = "usb2-phy";
			dr_mode = "peripheral";
			qcom,select-utmi-as-pipe-clk;

			ports {
				#address-cells = <1>;
				#size-cells = <0>;

				port@0 {
					reg = <0>;

					usb_1_dwc3_hs: endpoint {
						remote-endpoint = <&pmic_glink_hs_in>;
					};
				};

				port@1 {
					reg = <1>;

					usb_1_dwc3_ss: endpoint {
						remote-endpoint = <&usb_1_qmpphy_usb_ss_in>;
					};
				};
			};
		};

		tsens0: thermal-sensor@c263000 {
			compatible = "qcom,sm4450-tsens", "qcom,tsens-v2";
			reg = <0x0 0x0c263000 0x0 0x1ff>,
			      <0x0 0x0c222000 0x0 0x8>;
			#qcom,sensors = <16>;
			interrupts = <GIC_SPI 506 IRQ_TYPE_LEVEL_HIGH>,
				     <GIC_SPI 508 IRQ_TYPE_LEVEL_HIGH>;
			interrupt-names = "uplow", "critical";
			#thermal-sensor-cells = <1>;
		};

		tsens1: thermal-sensor@c265000 {
			compatible = "qcom,sm4450-tsens", "qcom,tsens-v2";
			reg = <0x0 0x0c265000 0x0 0x1ff>,
		    	  <0x0 0x0c223000 0x0 0x8>;
			#qcom,sensors = <6>;
			interrupts = <GIC_SPI 507 IRQ_TYPE_LEVEL_HIGH>,
				     <GIC_SPI 509 IRQ_TYPE_LEVEL_HIGH>;
			interrupt-names = "uplow", "critical";
			#thermal-sensor-cells = <1>;
		};

		aoss_qmp: power-management@c300000 {
			compatible = "qcom,sm4450-aoss-qmp", "qcom,aoss-qmp";
			reg = <0x0 0x0c300000 0x0 0x400>;
			interrupt-parent = <&ipcc>;
			interrupts-extended = <&ipcc IPCC_CLIENT_AOP
						     IPCC_MPROC_SIGNAL_GLINK_QMP
						     IRQ_TYPE_EDGE_RISING>;
			mboxes = <&ipcc IPCC_CLIENT_AOP IPCC_MPROC_SIGNAL_GLINK_QMP>;
			#clock-cells = <0>;
		};

		sdhc_1: mmc@7c4000 {
			compatible = "qcom,sm4450-sdhci", "qcom,sdhci-msm-v5";
			reg = <0x0 0x007c4000 0x0 0x1000>,
			      <0x0 0x007c5000 0x0 0x1000>;
			reg-names = "hc", "cqhci";
			interrupts = <GIC_SPI 135 IRQ_TYPE_LEVEL_HIGH>,
				     <GIC_SPI 137 IRQ_TYPE_LEVEL_HIGH>;
			interrupt-names = "hc_irq", "pwr_irq";
			clocks = <&gcc GCC_SDCC1_AHB_CLK>,
				 <&gcc GCC_SDCC1_APPS_CLK>,
				 <&rpmhcc RPMH_CXO_CLK>;
			clock-names = "iface", "core", "xo";
			power-domains = <&rpmhpd RPMHPD_CX>;
			bus-width = <8>;
			supports-cqe;
			non-removable;
			status = "disabled";
		};

		spmi_bus: spmi@c400000 {
			compatible = "qcom,spmi-pmic-arb";
			reg = <0x0 0x0c400000 0x0 0x3000>,
		    	  <0x0 0x0c500000 0x0 0x400000>,
		    	  <0x0 0x0c440000 0x0 0x80000>,
		    	  <0x0 0x0c4c0000 0x0 0x10000>,
		    	  <0x0 0x0c42d000 0x0 0x4000>;
			reg-names = "core", "chnls", "obsrvr", "intr", "cnfg";
			interrupt-names = "periph_irq";
			interrupts-extended = <&pdc 1 IRQ_TYPE_LEVEL_HIGH>;
			qcom,ee = <0>;
			qcom,channel = <0>;
			#address-cells = <2>;
			#size-cells = <0>;
			interrupt-controller;
			#interrupt-cells = <4>;
			status = "okay";
		};

		sdhc_2: mmc@8804000 {
			compatible = "qcom,sm4450-sdhci", "qcom,sdhci-msm-v5";
			reg = <0x0 0x08804000 0x0 0x1000>;
			reg-names = "hc";
			interrupts = <GIC_SPI 207 IRQ_TYPE_LEVEL_HIGH>,
				     <GIC_SPI 223 IRQ_TYPE_LEVEL_HIGH>;
			interrupt-names = "hc_irq", "pwr_irq";
			clocks = <&gcc GCC_SDCC2_AHB_CLK>,
				 <&gcc GCC_SDCC2_APPS_CLK>,
				 <&rpmhcc RPMH_CXO_CLK>;
			clock-names = "iface", "core", "xo";
			iommus = <&apps_smmu 0x140 0x0>;
			interconnects = <&aggre1_noc MASTER_SDCC_2 QCOM_ICC_TAG_ALWAYS
					 &mc_virt SLAVE_EBI1 QCOM_ICC_TAG_ALWAYS>,
					<&gem_noc MASTER_APPSS_PROC QCOM_ICC_TAG_ALWAYS
					 &config_noc SLAVE_SDCC_2 QCOM_ICC_TAG_ALWAYS>;
			interconnect-names = "sdhc-ddr", "cpu-sdhc";
			power-domains = <&rpmhpd RPMHPD_CX>;
			pinctrl-0 = <&sdc2_default>;
			pinctrl-names = "default";
			vmmc-supply = <&vreg_pbs_sd>;
			vqmmc-supply = <&vreg_pbs_px2>;
			bus-width = <4>;
			cd-gpios = <&tlmm 101 GPIO_ACTIVE_LOW>;
			no-sdio;
			status = "disabled";
		};

		ufs_mem_hc: ufshc@1d84000 {
			compatible = "qcom,sm4450-ufshc", "qcom,ufshc",
				     "jedec,ufs-2.0";
			reg = <0x0 0x01d84000 0x0 0x3000>;
			interrupts = <GIC_SPI 265 IRQ_TYPE_LEVEL_HIGH>;
			phys = <&ufs_mem_phy>;
			phy-names = "ufsphy";
			lanes-per-direction = <2>;
			#reset-cells = <1>;
			resets = <&gcc GCC_UFS_PHY_BCR>;
			reset-names = "rst";
			reset-gpios = <&tlmm 136 GPIO_ACTIVE_LOW>;
			power-domains = <&gcc GCC_UFS_PHY_GDSC>;
			iommus = <&apps_smmu 0x580 0x0>;
			dma-coherent;

			clock-names = "core_clk",
				      "bus_aggr_clk",
				      "iface_clk",
				      "core_clk_unipro",
				      "ref_clk",
				      "tx_lane0_sync_clk",
				      "rx_lane0_sync_clk",
				      "rx_lane1_sync_clk";
			clocks = <&gcc GCC_UFS_PHY_AXI_CLK>,
				 <&gcc GCC_AGGRE_UFS_PHY_AXI_CLK>,
				 <&gcc GCC_UFS_PHY_AHB_CLK>,
				 <&gcc GCC_UFS_PHY_UNIPRO_CORE_CLK>,
				 <&rpmhcc RPMH_CXO_CLK>,
				 <&gcc GCC_UFS_PHY_TX_SYMBOL_0_CLK>,
				 <&gcc GCC_UFS_PHY_RX_SYMBOL_0_CLK>,
				 <&gcc GCC_UFS_PHY_RX_SYMBOL_1_CLK>;
			freq-table-hz = <75000000 300000000>,
					<0 0>,
					<0 0>,
					<75000000 300000000>,
					<0 0>,
					<0 0>,
					<0 0>,
					<0 0>;
			interconnects = <&aggre2_noc MASTER_UFS_MEM QCOM_ICC_TAG_ALWAYS
					 &mc_virt SLAVE_EBI1 QCOM_ICC_TAG_ALWAYS>,
					<&gem_noc MASTER_APPSS_PROC QCOM_ICC_TAG_ALWAYS
					 &config_noc SLAVE_UFS_MEM_CFG QCOM_ICC_TAG_ALWAYS>;
			interconnect-names = "ufs-ddr", "cpu-ufs";

			vcc-supply = <&vreg_l5e_2p95>;
			vcc-max-microamp = <1056000>;
			vccq-supply = <&vreg_l13b_1p2>;
			vccq-max-microamp = <750000>;
			vccq2-supply = <&vreg_l19b_1p8>;
			vccq2-max-microamp = <750000>;

			status = "disabled";
		};

		ufs_mem_phy: phy@1d87000 {
			compatible = "qcom,sm4450-qmp-ufs-phy";
			reg = <0x0 0x01d87000 0x0 0x1000>;
			clocks = <&rpmhcc RPMH_CXO_CLK>,
				 <&gcc GCC_UFS_PHY_PHY_AUX_CLK>,
				 <&gcc GCC_UFS_0_CLKREF_EN>;
			clock-names = "ref",
			    	  "ref_aux",
				      "qref";
			power-domains = <&gcc GCC_UFS_PHY_GDSC>;
			resets = <&ufs_mem_hc 0>;
			reset-names = "ufsphy";
			vdda-phy-supply = <&vreg_l5b_0p88>;
			vdda-pll-supply = <&vreg_l16b_1p2>;
			#clock-cells = <1>;
			#phy-cells = <0>;
			status = "disabled";
		};


		pdc: interrupt-controller@b220000 {
			compatible = "qcom,sm4450-pdc", "qcom,pdc";
			reg = <0 0x0b220000 0 0x10000>, <0 0x174000f0 0 0x64>;
			qcom,pdc-ranges = <0 480 94>, <94 494 31>,
					  <125 63 1>;
			#interrupt-cells = <2>;
			interrupt-parent = <&intc>;
			interrupt-controller;
		};

		tlmm: pinctrl@f100000 {
			compatible = "qcom,sm4450-tlmm";
			reg = <0x0 0x0f100000 0x0 0x300000>;
			interrupts = <GIC_SPI 208 IRQ_TYPE_LEVEL_HIGH>;
			gpio-controller;
			#gpio-cells = <2>;
			interrupt-controller;
			#interrupt-cells = <2>;
			gpio-ranges = <&tlmm 0 0 137>;
			wakeup-parent = <&pdc>;

			qup_uart7_rx: qup-uart7-rx-state {
				pins = "gpio23";
				function = "qup1_se2_l2";
				drive-strength = <2>;
				bias-disable;
			};

			qup_uart7_tx: qup-uart7-tx-state {
				pins = "gpio22";
				function = "qup1_se2_l2";
				drive-strength = <2>;
				bias-disable;
			};
		};

		apps_smmu: iommu@15000000 {
			compatible = "qcom,sm4450-smmu-500", "qcom,smmu-500",
				     "arm,mmu-500";
			reg = <0x0 0x15000000 0x0 0x100000>;
			#iommu-cells = <2>;
			#global-interrupts = <1>;
			dma-coherent;

			interrupts = <GIC_SPI 65 IRQ_TYPE_LEVEL_HIGH>,
				<GIC_SPI 94 IRQ_TYPE_LEVEL_HIGH>,
				<GIC_SPI 95 IRQ_TYPE_LEVEL_HIGH>,
				<GIC_SPI 96 IRQ_TYPE_LEVEL_HIGH>,
				<GIC_SPI 670 IRQ_TYPE_LEVEL_HIGH>,
				<GIC_SPI 671 IRQ_TYPE_LEVEL_HIGH>,
				<GIC_SPI 97 IRQ_TYPE_LEVEL_HIGH>,
				<GIC_SPI 98 IRQ_TYPE_LEVEL_HIGH>,
				<GIC_SPI 99 IRQ_TYPE_LEVEL_HIGH>,
				<GIC_SPI 100 IRQ_TYPE_LEVEL_HIGH>,
				<GIC_SPI 101 IRQ_TYPE_LEVEL_HIGH>,
				<GIC_SPI 102 IRQ_TYPE_LEVEL_HIGH>,
				<GIC_SPI 103 IRQ_TYPE_LEVEL_HIGH>,
				<GIC_SPI 104 IRQ_TYPE_LEVEL_HIGH>,
				<GIC_SPI 105 IRQ_TYPE_LEVEL_HIGH>,
				<GIC_SPI 106 IRQ_TYPE_LEVEL_HIGH>,
				<GIC_SPI 107 IRQ_TYPE_LEVEL_HIGH>,
				<GIC_SPI 108 IRQ_TYPE_LEVEL_HIGH>,
				<GIC_SPI 109 IRQ_TYPE_LEVEL_HIGH>,
				<GIC_SPI 110 IRQ_TYPE_LEVEL_HIGH>,
				<GIC_SPI 111 IRQ_TYPE_LEVEL_HIGH>,
				<GIC_SPI 112 IRQ_TYPE_LEVEL_HIGH>,
				<GIC_SPI 113 IRQ_TYPE_LEVEL_HIGH>,
				<GIC_SPI 114 IRQ_TYPE_LEVEL_HIGH>,
				<GIC_SPI 115 IRQ_TYPE_LEVEL_HIGH>,
				<GIC_SPI 116 IRQ_TYPE_LEVEL_HIGH>,
				<GIC_SPI 117 IRQ_TYPE_LEVEL_HIGH>,
				<GIC_SPI 118 IRQ_TYPE_LEVEL_HIGH>,
				<GIC_SPI 181 IRQ_TYPE_LEVEL_HIGH>,
				<GIC_SPI 182 IRQ_TYPE_LEVEL_HIGH>,
				<GIC_SPI 183 IRQ_TYPE_LEVEL_HIGH>,
				<GIC_SPI 184 IRQ_TYPE_LEVEL_HIGH>,
				<GIC_SPI 185 IRQ_TYPE_LEVEL_HIGH>,
				<GIC_SPI 186 IRQ_TYPE_LEVEL_HIGH>,
				<GIC_SPI 187 IRQ_TYPE_LEVEL_HIGH>,
				<GIC_SPI 188 IRQ_TYPE_LEVEL_HIGH>,
				<GIC_SPI 189 IRQ_TYPE_LEVEL_HIGH>,
				<GIC_SPI 190 IRQ_TYPE_LEVEL_HIGH>,
				<GIC_SPI 191 IRQ_TYPE_LEVEL_HIGH>,
				<GIC_SPI 192 IRQ_TYPE_LEVEL_HIGH>,
				<GIC_SPI 315 IRQ_TYPE_LEVEL_HIGH>,
				<GIC_SPI 316 IRQ_TYPE_LEVEL_HIGH>,
				<GIC_SPI 317 IRQ_TYPE_LEVEL_HIGH>,
				<GIC_SPI 318 IRQ_TYPE_LEVEL_HIGH>,
				<GIC_SPI 319 IRQ_TYPE_LEVEL_HIGH>,
				<GIC_SPI 320 IRQ_TYPE_LEVEL_HIGH>,
				<GIC_SPI 321 IRQ_TYPE_LEVEL_HIGH>,
				<GIC_SPI 322 IRQ_TYPE_LEVEL_HIGH>,
				<GIC_SPI 323 IRQ_TYPE_LEVEL_HIGH>,
				<GIC_SPI 324 IRQ_TYPE_LEVEL_HIGH>,
				<GIC_SPI 325 IRQ_TYPE_LEVEL_HIGH>,
				<GIC_SPI 326 IRQ_TYPE_LEVEL_HIGH>,
				<GIC_SPI 327 IRQ_TYPE_LEVEL_HIGH>,
				<GIC_SPI 328 IRQ_TYPE_LEVEL_HIGH>,
				<GIC_SPI 329 IRQ_TYPE_LEVEL_HIGH>,
				<GIC_SPI 330 IRQ_TYPE_LEVEL_HIGH>,
				<GIC_SPI 331 IRQ_TYPE_LEVEL_HIGH>,
				<GIC_SPI 332 IRQ_TYPE_LEVEL_HIGH>,
				<GIC_SPI 333 IRQ_TYPE_LEVEL_HIGH>,
				<GIC_SPI 334 IRQ_TYPE_LEVEL_HIGH>,
				<GIC_SPI 335 IRQ_TYPE_LEVEL_HIGH>,
				<GIC_SPI 336 IRQ_TYPE_LEVEL_HIGH>,
				<GIC_SPI 337 IRQ_TYPE_LEVEL_HIGH>,
				<GIC_SPI 338 IRQ_TYPE_LEVEL_HIGH>,
				<GIC_SPI 339 IRQ_TYPE_LEVEL_HIGH>,
				<GIC_SPI 340 IRQ_TYPE_LEVEL_HIGH>,
				<GIC_SPI 341 IRQ_TYPE_LEVEL_HIGH>,
				<GIC_SPI 342 IRQ_TYPE_LEVEL_HIGH>,
				<GIC_SPI 343 IRQ_TYPE_LEVEL_HIGH>,
				<GIC_SPI 344 IRQ_TYPE_LEVEL_HIGH>,
				<GIC_SPI 345 IRQ_TYPE_LEVEL_HIGH>,
				<GIC_SPI 395 IRQ_TYPE_LEVEL_HIGH>,
				<GIC_SPI 396 IRQ_TYPE_LEVEL_HIGH>,
				<GIC_SPI 397 IRQ_TYPE_LEVEL_HIGH>,
				<GIC_SPI 398 IRQ_TYPE_LEVEL_HIGH>,
				<GIC_SPI 399 IRQ_TYPE_LEVEL_HIGH>,
				<GIC_SPI 400 IRQ_TYPE_LEVEL_HIGH>,
				<GIC_SPI 401 IRQ_TYPE_LEVEL_HIGH>,
				<GIC_SPI 402 IRQ_TYPE_LEVEL_HIGH>,
				<GIC_SPI 403 IRQ_TYPE_LEVEL_HIGH>,
				<GIC_SPI 404 IRQ_TYPE_LEVEL_HIGH>,
				<GIC_SPI 405 IRQ_TYPE_LEVEL_HIGH>,
				<GIC_SPI 406 IRQ_TYPE_LEVEL_HIGH>,
				<GIC_SPI 407 IRQ_TYPE_LEVEL_HIGH>,
				<GIC_SPI 408 IRQ_TYPE_LEVEL_HIGH>,
				<GIC_SPI 409 IRQ_TYPE_LEVEL_HIGH>,
				<GIC_SPI 418 IRQ_TYPE_LEVEL_HIGH>,
				<GIC_SPI 419 IRQ_TYPE_LEVEL_HIGH>,
				<GIC_SPI 412 IRQ_TYPE_LEVEL_HIGH>,
				<GIC_SPI 421 IRQ_TYPE_LEVEL_HIGH>,
				<GIC_SPI 707 IRQ_TYPE_LEVEL_HIGH>,
				<GIC_SPI 423 IRQ_TYPE_LEVEL_HIGH>,
				<GIC_SPI 424 IRQ_TYPE_LEVEL_HIGH>,
				<GIC_SPI 425 IRQ_TYPE_LEVEL_HIGH>,
				<GIC_SPI 690 IRQ_TYPE_LEVEL_HIGH>,
				<GIC_SPI 691 IRQ_TYPE_LEVEL_HIGH>,
				<GIC_SPI 692 IRQ_TYPE_LEVEL_HIGH>;
		};

		qfprom: qfprom@221c8000 {
			compatible = "qcom,sm4450-qfprom", "qcom,qfprom";
			reg = <0x0 0x221c8000 0x0 0x1000>;
			#address-cells = <1>;
			#size-cells = <1>;
			read-only;

			gpu_speed_bin: gpu-speed-bin@119 {
				reg = <0x119 0x2>;
				bits = <5 8>;
			};
		};

		gem_noc: interconnect@19100000 {
			compatible = "qcom,sm4450-gem-noc";
			reg = <0x0 0x19100000 0x0 0xbc080>;
			#interconnect-cells = <2>;
			qcom,bcm-voters = <&apps_bcm_voter>;
		};

		mmss_noc: interconnect@1740000 {
			compatible = "qcom,sm4450-mmss-noc";
			reg = <0x0 0x01740000 0x0 0x19080>;
			#interconnect-cells = <2>;
			qcom,bcm-voters = <&apps_bcm_voter>;
		};

		intc: interrupt-controller@17200000 {
			compatible = "arm,gic-v3";
			reg = <0x0 0x17200000 0x0 0x10000>,     /* GICD */
			      <0x0 0x17260000 0x0 0x100000>;    /* GICR * 8 */
			interrupts = <GIC_PPI 9 IRQ_TYPE_LEVEL_LOW>;
			#interrupt-cells = <3>;
			interrupt-controller;
			#redistributor-regions = <1>;
			redistributor-stride = <0x0 0x20000>;
		};

		timer@17420000 {
			compatible = "arm,armv7-timer-mem";
			reg = <0x0 0x17420000 0x0 0x1000>;
			ranges = <0 0 0 0x20000000>;
			#address-cells = <1>;
			#size-cells = <1>;

			frame@17421000 {
				reg = <0x17421000 0x1000>,
				      <0x17422000 0x1000>;
				frame-number = <0>;
				interrupts = <GIC_SPI 8 IRQ_TYPE_LEVEL_HIGH>,
					     <GIC_SPI 6 IRQ_TYPE_LEVEL_HIGH>;
			};

			frame@17423000 {
				reg = <0x17423000 0x1000>;
				frame-number = <1>;
				interrupts = <GIC_SPI 9 IRQ_TYPE_LEVEL_HIGH>;
				status = "disabled";
			};

			frame@17425000 {
				reg = <0x17425000 0x1000>;
				frame-number = <2>;
				interrupts = <GIC_SPI 10 IRQ_TYPE_LEVEL_HIGH>;
				status = "disabled";
			};

			frame@17427000 {
				reg = <0x17427000 0x1000>;
				frame-number = <3>;
				interrupts = <GIC_SPI 11 IRQ_TYPE_LEVEL_HIGH>;
				status = "disabled";
			};

			frame@17429000 {
				reg = <0x17429000 0x1000>;
				frame-number = <4>;
				interrupts = <GIC_SPI 12 IRQ_TYPE_LEVEL_HIGH>;
				status = "disabled";
			};

			frame@1742b000 {
				reg = <0x1742b000 0x1000>;
				frame-number = <5>;
				interrupts = <GIC_SPI 13 IRQ_TYPE_LEVEL_HIGH>;
				status = "disabled";
			};

			frame@1742d000 {
				reg = <0x1742d000 0x1000>;
				frame-number = <6>;
				interrupts = <GIC_SPI 14 IRQ_TYPE_LEVEL_HIGH>;
				status = "disabled";
			};
		};

		apps_rsc: rsc@17a00000 {
			compatible = "qcom,rpmh-rsc";
			reg = <0x0 0x17a00000 0x0 0x10000>,
			      <0x0 0x17a10000 0x0 0x10000>,
			      <0x0 0x17a20000 0x0 0x10000>;
			reg-names = "drv-0", "drv-1", "drv-2";
			interrupts = <GIC_SPI 3 IRQ_TYPE_LEVEL_HIGH>,
				     <GIC_SPI 4 IRQ_TYPE_LEVEL_HIGH>,
				     <GIC_SPI 5 IRQ_TYPE_LEVEL_HIGH>;
			label = "apps_rsc";
			qcom,tcs-offset = <0xd00>;
			qcom,drv-id = <2>;
			qcom,tcs-config = <ACTIVE_TCS    2>, <SLEEP_TCS     3>,
					  <WAKE_TCS      3>, <CONTROL_TCS   0>;
			power-domains = <&cluster_pd>;

			apps_bcm_voter: bcm-voter {
				compatible = "qcom,bcm-voter";
			};

			rpmhcc: clock-controller {
				compatible = "qcom,sm4450-rpmh-clk";
				#clock-cells = <1>;
				clocks = <&xo_board>;
				clock-names = "xo";
			};

			rpmhpd: power-controller {
				compatible = "qcom,sm4450-rpmhpd";
				#power-domain-cells = <1>;
				operating-points-v2 = <&rpmhpd_opp_table>;

				rpmhpd_opp_table: opp-table {
					compatible = "operating-points-v2";

					rpmhpd_opp_ret: opp-16 {
						opp-level = <RPMH_REGULATOR_LEVEL_RETENTION>;
					};

					rpmhpd_opp_min_svs: opp-48 {
						opp-level = <RPMH_REGULATOR_LEVEL_MIN_SVS>;
					};

					rpmhpd_opp_low_svs_d1: opp-56 {
						opp-level = <RPMH_REGULATOR_LEVEL_LOW_SVS_D1>;
					};

					rpmhpd_opp_low_svs: opp-64 {
						opp-level = <RPMH_REGULATOR_LEVEL_LOW_SVS>;
					};

					rpmhpd_opp_low_svs_l1: opp-80 {
						opp-level = <RPMH_REGULATOR_LEVEL_LOW_SVS_L1>;
					};

					rpmhpd_opp_low_svs_l2: opp-96 {
						opp-level = <RPMH_REGULATOR_LEVEL_LOW_SVS_L2>;
					};

					rpmhpd_opp_svs: opp-128 {
						opp-level = <RPMH_REGULATOR_LEVEL_SVS>;
					};

					rpmhpd_opp_svs_l1: opp-192 {
						opp-level = <RPMH_REGULATOR_LEVEL_SVS_L1>;
					};

					rpmhpd_opp_svs_l2: opp-224 {
						opp-level = <RPMH_REGULATOR_LEVEL_SVS_L2>;
					};

					rpmhpd_opp_nom: opp-256 {
						opp-level = <RPMH_REGULATOR_LEVEL_NOM>;
					};

					rpmhpd_opp_nom_l1: opp-320 {
						opp-level = <RPMH_REGULATOR_LEVEL_NOM_L1>;
					};

					rpmhpd_opp_nom_l2: opp-336 {
						opp-level = <RPMH_REGULATOR_LEVEL_NOM_L2>;
					};

					rpmhpd_opp_turbo: opp-384 {
						opp-level = <RPMH_REGULATOR_LEVEL_TURBO>;
					};

					rpmhpd_opp_turbo_l1: opp-416 {
						opp-level = <RPMH_REGULATOR_LEVEL_TURBO_L1>;
					};
				};
			};
		};

		cpufreq_hw: cpufreq@17d91000 {
			compatible = "qcom,sm4450-cpufreq-epss", "qcom,cpufreq-epss";
			reg = <0 0x17d91000 0 0x1000>,
			      <0 0x17d92000 0 0x1000>;
			reg-names = "freq-domain0", "freq-domain1";
			clocks = <&bi_tcxo_div2>, <&gcc GCC_GPLL0>;
			clock-names = "xo", "alternate";
			interrupts = <GIC_SPI 30 IRQ_TYPE_LEVEL_HIGH>,
				     <GIC_SPI 31 IRQ_TYPE_LEVEL_HIGH>;
			interrupt-names = "dcvsh-irq-0", "dcvsh-irq-1";
			#freq-domain-cells = <1>;
			#clock-cells = <1>;
		};
	};

	thermal-zones {
		aoss0-thermal {
			thermal-sensors = <&tsens0 0>;

			trips {
				aoss0_alert: trip-point0 {
					temperature = <95000>;
					hysteresis = <2000>;
					type = "passive";
				};

				aoss0-crit {
					temperature = <115000>;
					hysteresis = <0>;
					type = "critical";
				};
			};
		};

		cpu0-thermal {
			thermal-sensors = <&tsens0 1>;

			trips {
				cpu0_alert: trip-point0 {
					temperature = <95000>;
					hysteresis = <2000>;
					type = "passive";
				};

				cpu0-crit {
					temperature = <115000>;
					hysteresis = <0>;
					type = "critical";
				};
			};

			cooling-maps {
				map0 {
					trip = <&cpu0_alert>;
					cooling-device = <&cpu0 THERMAL_NO_LIMIT THERMAL_NO_LIMIT>;
				};
			};
		};

		cpu1-thermal {
			thermal-sensors = <&tsens0 2>;

			trips {
				cpu1_alert: trip-point0 {
					temperature = <95000>;
					hysteresis = <2000>;
					type = "passive";
				};

				cpu1-crit {
					temperature = <115000>;
					hysteresis = <0>;
					type = "critical";
				};
			};

			cooling-maps {
				map0 {
					trip = <&cpu1_alert>;
					cooling-device = <&cpu1 THERMAL_NO_LIMIT THERMAL_NO_LIMIT>;
				};
			};
		};

		cpu2-thermal {
			thermal-sensors = <&tsens0 3>;

			trips {
				cpu2_alert: trip-point0 {
					temperature = <95000>;
					hysteresis = <2000>;
					type = "passive";
				};

				cpu2-crit {
					temperature = <115000>;
					hysteresis = <0>;
					type = "critical";
				};
			};

			cooling-maps {
				map0 {
					trip = <&cpu2_alert>;
					cooling-device = <&cpu2 THERMAL_NO_LIMIT THERMAL_NO_LIMIT>;
				};
			};
		};

		cpu3-thermal {
			thermal-sensors = <&tsens0 4>;

			trips {
				cpu3_alert: trip-point0 {
					temperature = <95000>;
					hysteresis = <2000>;
					type = "passive";
				};

				cpu3-crit {
					temperature = <115000>;
					hysteresis = <0>;
					type = "critical";
				};
			};

			cooling-maps {
				map0 {
					trip = <&cpu3_alert>;
					cooling-device = <&cpu3 THERMAL_NO_LIMIT THERMAL_NO_LIMIT>;
				};
			};
		};

		cpu4-thermal {
			thermal-sensors = <&tsens0 5>;

			trips {
				cpu4_alert: trip-point0 {
					temperature = <95000>;
					hysteresis = <2000>;
					type = "passive";
				};

				cpu4-crit {
					temperature = <115000>;
					hysteresis = <0>;
					type = "critical";
				};
			};

			cooling-maps {
				map0 {
					trip = <&cpu4_alert>;
					cooling-device = <&cpu4 THERMAL_NO_LIMIT THERMAL_NO_LIMIT>;
				};
			};
		};

		cpu5-thermal {
			thermal-sensors = <&tsens0 6>;

			trips {
				cpu5_alert: trip-point0 {
					temperature = <95000>;
					hysteresis = <2000>;
					type = "passive";
				};

				cpu5-crit {
					temperature = <115000>;
					hysteresis = <0>;
					type = "critical";
				};
			};

			cooling-maps {
				map0 {
					trip = <&cpu5_alert>;
					cooling-device = <&cpu5 THERMAL_NO_LIMIT THERMAL_NO_LIMIT>;
				};
			};
		};

		cpuss0-thermal {
			thermal-sensors = <&tsens0 7>;

			trips {
				cpuss0_alert: trip-point0 {
					temperature = <95000>;
					hysteresis = <2000>;
					type = "passive";
				};

				cpuss0-crit {
					temperature = <115000>;
					hysteresis = <0>;
					type = "critical";
				};
			};
		};

		cpuss1-thermal {
			thermal-sensors = <&tsens0 8>;

			trips {
				cpuss1_alert: trip-point0 {
					temperature = <95000>;
					hysteresis = <2000>;
					type = "passive";
				};

				cpuss1-crit {
					temperature = <115000>;
					hysteresis = <0>;
					type = "critical";
				};
			};
		};

		cpu6-0-thermal {
			thermal-sensors = <&tsens0 9>;

			trips {
				cpu6_0_alert: trip-point0 {
					temperature = <95000>;
					hysteresis = <2000>;
					type = "passive";
				};

				cpu6_0-crit {
					temperature = <115000>;
					hysteresis = <0>;
					type = "critical";
				};
			};

			cooling-maps {
				map0 {
					trip = <&cpu6_0_alert>;
					cooling-device = <&cpu6 THERMAL_NO_LIMIT THERMAL_NO_LIMIT>;
				};
			};
		};

		cpu6-1-thermal {
			thermal-sensors = <&tsens0 10>;

			trips {
				cpu6_1_alert: trip-point0 {
					temperature = <95000>;
					hysteresis = <2000>;
					type = "passive";
				};

				cpu6_1-crit {
					temperature = <115000>;
					hysteresis = <0>;
					type = "critical";
				};
			};

			cooling-maps {
				map0 {
					trip = <&cpu6_1_alert>;
					cooling-device = <&cpu6 THERMAL_NO_LIMIT THERMAL_NO_LIMIT>;
				};
			};
		};

		cpu7-0-thermal {
			thermal-sensors = <&tsens0 11>;

			trips {
				cpu7_0_alert: trip-point0 {
					temperature = <95000>;
					hysteresis = <2000>;
					type = "passive";
				};

				cpu7_0-crit {
					temperature = <115000>;
					hysteresis = <0>;
					type = "critical";
				};
			};

			cooling-maps {
				map0 {
					trip = <&cpu7_0_alert>;
					cooling-device = <&cpu7 THERMAL_NO_LIMIT THERMAL_NO_LIMIT>;
				};
			};
		};

		cpu7-1-thermal {
			thermal-sensors = <&tsens0 12>;

			trips {
				cpu7_1_alert: trip-point0 {
					temperature = <95000>;
					hysteresis = <2000>;
					type = "passive";
				};

				cpu7_1-crit {
					temperature = <115000>;
					hysteresis = <0>;
					type = "critical";
				};
			};

			cooling-maps {
				map0 {
					trip = <&cpu7_1_alert>;
					cooling-device = <&cpu7 THERMAL_NO_LIMIT THERMAL_NO_LIMIT>;
				};
			};
		};

		gpu-thermal {
			thermal-sensors = <&tsens0 13>;

			trips {
				gpu_alert: trip-point0 {
					temperature = <95000>;
					hysteresis = <2000>;
					type = "passive";
				};

				gpu-crit {
					temperature = <115000>;
					hysteresis = <0>;
					type = "critical";
				};
			};
		};

		camera-thermal {
			thermal-sensors = <&tsens0 14>;

			trips {
				camera_alert: trip-point0 {
					temperature = <95000>;
					hysteresis = <2000>;
					type = "passive";
				};

				camera-crit {
					temperature = <115000>;
					hysteresis = <0>;
					type = "critical";
				};
			};
		};

		video-thermal {
			thermal-sensors = <&tsens0 15>;

			trips {
				video_alert: trip-point0 {
					temperature = <95000>;
					hysteresis = <2000>;
					type = "passive";
				};

				video-crit {
					temperature = <115000>;
					hysteresis = <0>;
					type = "critical";
				};
			};
		};

		aoss1-thermal {
			thermal-sensors = <&tsens1 0>;

			trips {
				aoss1_alert: trip-point0 {
					temperature = <95000>;
					hysteresis = <2000>;
					type = "passive";
				};

				aoss1-crit {
					temperature = <115000>;
					hysteresis = <0>;
					type = "critical";
				};
			};
		};

		ddr-thermal {
			thermal-sensors = <&tsens1 1>;

			trips {
				ddr_alert: trip-point0 {
					temperature = <95000>;
					hysteresis = <2000>;
					type = "passive";
				};

				ddr-crit {
					temperature = <115000>;
					hysteresis = <0>;
					type = "critical";
				};
			};
		};

		modem0-thermal {
			thermal-sensors = <&tsens1 2>;

			trips {
				modem0_alert: trip-point0 {
					temperature = <95000>;
					hysteresis = <2000>;
					type = "passive";
				};

				modem0-crit {
					temperature = <115000>;
					hysteresis = <0>;
					type = "critical";
				};
			};
		};

		modem1-thermal {
			thermal-sensors = <&tsens1 3>;

			trips {
				modem1_alert: trip-point0 {
					temperature = <95000>;
					hysteresis = <2000>;
					type = "passive";
				};

				modem1-crit {
					temperature = <115000>;
					hysteresis = <0>;
					type = "critical";
				};
			};
		};

		modem2-thermal {
			thermal-sensors = <&tsens1 4>;

			trips {
				modem2_alert: trip-point0 {
					temperature = <95000>;
					hysteresis = <2000>;
					type = "passive";
				};

				modem2-crit {
					temperature = <115000>;
					hysteresis = <0>;
					type = "critical";
				};
			};
		};

		modem3-thermal {
			thermal-sensors = <&tsens1 5>;

			trips {
				modem3_alert: trip-point0 {
					temperature = <95000>;
					hysteresis = <2000>;
					type = "passive";
				};

				modem3-crit {
					temperature = <115000>;
					hysteresis = <0>;
					type = "critical";
				};
			};
		};
	};

	timer {
		compatible = "arm,armv8-timer";
		interrupts = <GIC_PPI 13 IRQ_TYPE_LEVEL_LOW>,
			     <GIC_PPI 14 IRQ_TYPE_LEVEL_LOW>,
			     <GIC_PPI 11 IRQ_TYPE_LEVEL_LOW>,
			     <GIC_PPI 10 IRQ_TYPE_LEVEL_LOW>;
	};
};
